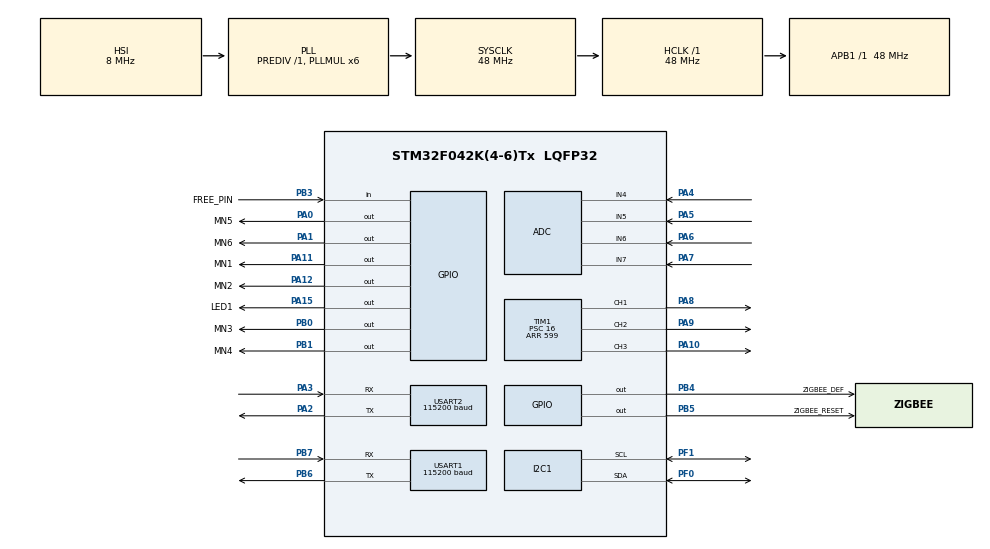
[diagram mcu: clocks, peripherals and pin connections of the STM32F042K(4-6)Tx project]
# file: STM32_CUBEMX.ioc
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ADC.ClockPrescaler=ADC_CLOCK_SYNC_PCLK_DIV4
ADC.ContinuousConvMode=ENABLE
ADC.DMAContinuousRequests=DISABLE
ADC.DiscontinuousConvMode=DISABLE
ADC.EOCSelection=ADC_EOC_SEQ_CONV
ADC.SamplingTime=ADC_SAMPLETIME_13CYCLES_5
ADC.ScanConvMode=ADC_SCAN_DIRECTION_FORWARD
Dma.ADC.0.Direction=DMA_PERIPH_TO_MEMORY
Dma.ADC.0.Instance=DMA1_Channel1
Dma.ADC.0.MemDataAlignment=DMA_MDATAALIGN_WORD
Dma.ADC.0.MemInc=DMA_MINC_ENABLE
Dma.ADC.0.Mode=DMA_NORMAL
Dma.ADC.0.PeriphDataAlignment=DMA_PDATAALIGN_WORD
Dma.ADC.0.PeriphInc=DMA_PINC_DISABLE
Dma.ADC.0.Priority=DMA_PRIORITY_MEDIUM
Dma.Request0=ADC
Mcu.Family=STM32F0
Mcu.Name=STM32F042K(4-6)Tx
Mcu.Package=LQFP32
NVIC.ADC1_IRQn=true\:0\:0\:false\:true\:true\:2\:true\:true
NVIC.DMA1_Channel1_IRQn=true\:0\:0\:false\:true\:true\:1\:false\:true
NVIC.TIM1_BRK_UP_TRG_COM_IRQn=true\:0\:0\:false\:true\:true\:3\:true\:true
NVIC.TIM1_CC_IRQn=true\:0\:0\:false\:false\:true\:true\:true
NVIC.USART1_IRQn=true\:0\:0\:false\:true\:true\:4\:true\:true
NVIC.USART2_IRQn=true\:0\:0\:false\:true\:true\:5\:true\:true
PA0.GPIO_Label=MN5
PA0.GPIO_Speed=GPIO_SPEED_FREQ_HIGH
PA0.Signal=GPIO_Output
PA1.GPIO_Label=MN6
PA1.GPIO_Speed=GPIO_SPEED_FREQ_HIGH
PA1.Signal=GPIO_Output
PA10.Signal=S_TIM1_CH3
PA11.GPIO_Label=MN1
PA11.GPIO_Speed=GPIO_SPEED_FREQ_HIGH
PA11.Signal=GPIO_Output
PA12.GPIO_Label=MN2
PA12.GPIO_Speed=GPIO_SPEED_FREQ_HIGH
PA12.Signal=GPIO_Output
PA13.Mode=Serial_Wire
PA13.Signal=SYS_SWDIO
PA14.Mode=Serial_Wire
PA14.Signal=SYS_SWCLK
PA15.GPIO_Label=LED1
PA15.PinState=GPIO_PIN_SET
PA15.Signal=GPIO_Output
PA2.Mode=Asynchronous
PA2.Signal=USART2_TX
PA3.Mode=Asynchronous
PA3.Signal=USART2_RX
PA4.Mode=IN4
PA4.Signal=ADC_IN4
PA5.Mode=IN5
PA5.Signal=ADC_IN5
PA6.Mode=IN6
PA6.Signal=ADC_IN6
PA7.Mode=IN7
PA7.Signal=ADC_IN7
PA8.Signal=S_TIM1_CH1
PA9.Signal=S_TIM1_CH2
PB0.GPIO_Label=MN3
PB0.GPIO_Speed=GPIO_SPEED_FREQ_HIGH
PB0.Signal=GPIO_Output
PB1.GPIO_Label=MN4
PB1.GPIO_Speed=GPIO_SPEED_FREQ_HIGH
PB1.Signal=GPIO_Output
PB3.GPIO_Label=FREE_PIN
PB3.GPIO_PuPd=GPIO_PULLUP
PB3.Signal=GPIO_Input
PB4.GPIO_Label=ZIGBEE_DEF
PB4.GPIO_PuPd=GPIO_PULLUP
PB4.GPIO_Speed=GPIO_SPEED_FREQ_HIGH
PB4.PinState=GPIO_PIN_SET
PB4.Signal=GPIO_Output
PB5.GPIO_Label=ZIGBEE_RESET
PB5.GPIO_PuPd=GPIO_PULLUP
PB5.PinState=GPIO_PIN_SET
PB5.Signal=GPIO_Output
PB6.Mode=Asynchronous
PB6.Signal=USART1_TX
PB7.Mode=Asynchronous
PB7.Signal=USART1_RX
PF0-OSC_IN.Mode=I2C
PF0-OSC_IN.Signal=I2C1_SDA
PF1-OSC_OUT.Mode=I2C
PF1-OSC_OUT.Signal=I2C1_SCL
ProjectManager.HeapSize=0x200
ProjectManager.StackSize=0x400
ProjectManager.TargetToolchain=EWARM V8
RCC.AHBFreq_Value=48000000
RCC.APB1Freq_Value=48000000
RCC.APB1TimFreq_Value=48000000
RCC.HCLKFreq_Value=48000000
RCC.PLLMUL=RCC_PLL_MUL6
RCC.SYSCLKFreq_VALUE=48000000
RCC.SYSCLKSource=RCC_SYSCLKSOURCE_PLLCLK
RCC.TimSys_Div=SYSTICK_CLKSOURCE_HCLK_DIV8
SH.S_TIM1_CH1.0=TIM1_CH1,PWM Generation1 CH1
SH.S_TIM1_CH2.0=TIM1_CH2,PWM Generation2 CH2
SH.S_TIM1_CH3.0=TIM1_CH3,PWM Generation3 CH3
TIM1.AutoReloadPreload=TIM_AUTORELOAD_PRELOAD_DISABLE
TIM1.Channel-PWM\ Generation1\ CH1=TIM_CHANNEL_1
TIM1.Channel-PWM\ Generation2\ CH2=TIM_CHANNEL_2
TIM1.Channel-PWM\ Generation3\ CH3=TIM_CHANNEL_3
TIM1.Period=599
TIM1.Prescaler=16
USART1.BaudRate=115200
USART1.VirtualMode-Asynchronous=VM_ASYNC
USART2.BaudRate=115200
USART2.VirtualMode-Asynchronous=VM_ASYNC
VP_CRC_VS_CRC.Mode=CRC_Activate
VP_TIM1_VS_ClockSourceINT.Mode=Internal
VP_TIM1_VS_ClockSourceITR.Mode=TriggerSource_ITR0
VP_TIM1_VS_ControllerModeReset.Mode=Reset Mode
board=custom

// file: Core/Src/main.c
/* USER CODE BEGIN Header */
/**
  ******************************************************************************
  * @file           : main.c
  * @brief          : Main program body
  ******************************************************************************
  * @attention
  *
  * <h2><center>&copy; Copyright (c) 2019 STMicroelectronics.
  * All rights reserved.</center></h2>
  *
  * This software component is licensed by ST under BSD 3-Clause license,
  * the "License"; You may not use this file except in compliance with the
  * License. You may obtain a copy of the License at:
  *                        opensource.org/licenses/BSD-3-Clause
  *
  ******************************************************************************
  */
/* USER CODE END Header */

#include "main.h"
#include "adc.h"
#include "crc.h"
#include "dma.h"
#include "i2c.h"
#include "tim.h"
#include "usart.h"
#include "gpio.h"

/* USER CODE BEGIN Includes */
#include "application.h"
/* USER CODE END Includes */

void SystemClock_Config(void);
static void MX_NVIC_Init(void);

int main(void)
{

  /* MCU Configuration--------------------------------------------------------*/

  /* Reset of all peripherals, Initializes the Flash interface and the Systick. */
  HAL_Init();

  /* Configure the system clock */
  SystemClock_Config();

  /* Initialize all configured peripherals */
  MX_GPIO_Init();
  MX_DMA_Init();
  MX_ADC_Init();
  MX_CRC_Init();
  MX_I2C1_Init();
  MX_TIM1_Init();
  MX_USART1_UART_Init();
  MX_USART2_UART_Init();

  /* Initialize interrupts */
  MX_NVIC_Init();
  /* USER CODE BEGIN 2 */

  System_Startup();

  /* USER CODE END 2 */

  /* Infinite loop */
  while (1)
  {

  }
}

void SystemClock_Config(void)
{
  RCC_OscInitTypeDef RCC_OscInitStruct = {0};
  RCC_ClkInitTypeDef RCC_ClkInitStruct = {0};
  RCC_PeriphCLKInitTypeDef PeriphClkInit = {0};

  /** Initializes the CPU, AHB and APB busses clocks
  */
  RCC_OscInitStruct.OscillatorType = RCC_OSCILLATORTYPE_HSI;
  RCC_OscInitStruct.HSIState = RCC_HSI_ON;
  RCC_OscInitStruct.HSICalibrationValue = RCC_HSICALIBRATION_DEFAULT;
  RCC_OscInitStruct.PLL.PLLState = RCC_PLL_ON;
  RCC_OscInitStruct.PLL.PLLSource = RCC_PLLSOURCE_HSI;
  RCC_OscInitStruct.PLL.PLLMUL = RCC_PLL_MUL6;
  RCC_OscInitStruct.PLL.PREDIV = RCC_PREDIV_DIV1;
  if (HAL_RCC_OscConfig(&RCC_OscInitStruct) != HAL_OK)
  {
    Error_Handler();
  }
  /** Initializes the CPU, AHB and APB busses clocks
  */
  RCC_ClkInitStruct.ClockType = RCC_CLOCKTYPE_HCLK|RCC_CLOCKTYPE_SYSCLK
                              |RCC_CLOCKTYPE_PCLK1;
  RCC_ClkInitStruct.SYSCLKSource = RCC_SYSCLKSOURCE_PLLCLK;
  RCC_ClkInitStruct.AHBCLKDivider = RCC_SYSCLK_DIV1;
  RCC_ClkInitStruct.APB1CLKDivider = RCC_HCLK_DIV1;

  if (HAL_RCC_ClockConfig(&RCC_ClkInitStruct, FLASH_LATENCY_1) != HAL_OK)
  {
    Error_Handler();
  }
  PeriphClkInit.PeriphClockSelection = RCC_PERIPHCLK_USART1|RCC_PERIPHCLK_I2C1;
  PeriphClkInit.Usart1ClockSelection = RCC_USART1CLKSOURCE_PCLK1;
  PeriphClkInit.I2c1ClockSelection = RCC_I2C1CLKSOURCE_HSI;
  if (HAL_RCCEx_PeriphCLKConfig(&PeriphClkInit) != HAL_OK)
  {
    Error_Handler();
  }
}

/**
  * @brief NVIC Configuration.
  * @retval None
  */
static void MX_NVIC_Init(void)
{
  /* DMA1_Channel1_IRQn interrupt configuration */
  HAL_NVIC_SetPriority(DMA1_Channel1_IRQn, 0, 0);
  HAL_NVIC_EnableIRQ(DMA1_Channel1_IRQn);
  /* DMA1_Channel2_3_IRQn interrupt configuration */
  HAL_NVIC_SetPriority(DMA1_Channel2_3_IRQn, 0, 0);
  HAL_NVIC_EnableIRQ(DMA1_Channel2_3_IRQn);
  /* DMA1_Channel4_5_IRQn interrupt configuration */
  HAL_NVIC_SetPriority(DMA1_Channel4_5_IRQn, 0, 0);
  HAL_NVIC_EnableIRQ(DMA1_Channel4_5_IRQn);
  /* ADC1_IRQn interrupt configuration */
  HAL_NVIC_SetPriority(ADC1_IRQn, 0, 0);
  HAL_NVIC_EnableIRQ(ADC1_IRQn);
  /* TIM1_BRK_UP_TRG_COM_IRQn interrupt configuration */
  HAL_NVIC_SetPriority(TIM1_BRK_UP_TRG_COM_IRQn, 0, 0);
  HAL_NVIC_EnableIRQ(TIM1_BRK_UP_TRG_COM_IRQn);
  /* USART1_IRQn interrupt configuration */
  HAL_NVIC_SetPriority(USART1_IRQn, 0, 0);
  HAL_NVIC_EnableIRQ(USART1_IRQn);
  /* USART2_IRQn interrupt configuration */
  HAL_NVIC_SetPriority(USART2_IRQn, 0, 0);
  HAL_NVIC_EnableIRQ(USART2_IRQn);
}

void Error_Handler(void)
{
}

/************************ (C) COPYRIGHT STMicroelectronics *****END OF FILE****/
